AUTOSAR XML (schema 4-2-2)
package /Components
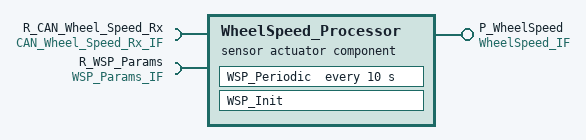
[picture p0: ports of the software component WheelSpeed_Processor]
  sensor actuator sw component type WheelSpeed_Processor
    provide port P_WheelSpeed: provided-interface=WheelSpeed_IF
    require port R_CAN_Wheel_Speed_Rx: required-interface=CAN_Wheel_Speed_Rx_IF
    require port R_WSP_Params: required-interface=WSP_Params_IF
    behavior WheelSpeed_Processor_InternalBehavior
      init event WSP_Init_Event: start-on-event=WSP_Init
      timing event WSP_Periodic_Event: start-on-event=WSP_Periodic, period=10
      runnable WSP_Init
        parameter access PA_Init_FilterTimeConstant: accessed-parameter=R_WSP_Params.wsp_filter_time_constant
        parameter access PA_Init_QualityThreshold: accessed-parameter=R_WSP_Params.wsp_quality_threshold
      runnable WSP_Periodic: minimum-start-interval=10
        data-receive-point-by-arguments:
          4 x access:
            VA_Rx_RawWS_FL: accessed-variable=R_CAN_Wheel_Speed_Rx.raw_wheel_speed_fl
            VA_Rx_RawWS_FR: accessed-variable=R_CAN_Wheel_Speed_Rx.raw_wheel_speed_fr
            VA_Rx_RawWS_RL: accessed-variable=R_CAN_Wheel_Speed_Rx.raw_wheel_speed_rl
            VA_Rx_RawWS_RR: accessed-variable=R_CAN_Wheel_Speed_Rx.raw_wheel_speed_rr
        data-send-points:
          4 x access:
            VA_Tx_WS_FL: accessed-variable=P_WheelSpeed.wheel_speed_fl
            VA_Tx_WS_FR: accessed-variable=P_WheelSpeed.wheel_speed_fr
            VA_Tx_WS_RL: accessed-variable=P_WheelSpeed.wheel_speed_rl
            VA_Tx_WS_RR: accessed-variable=P_WheelSpeed.wheel_speed_rr
